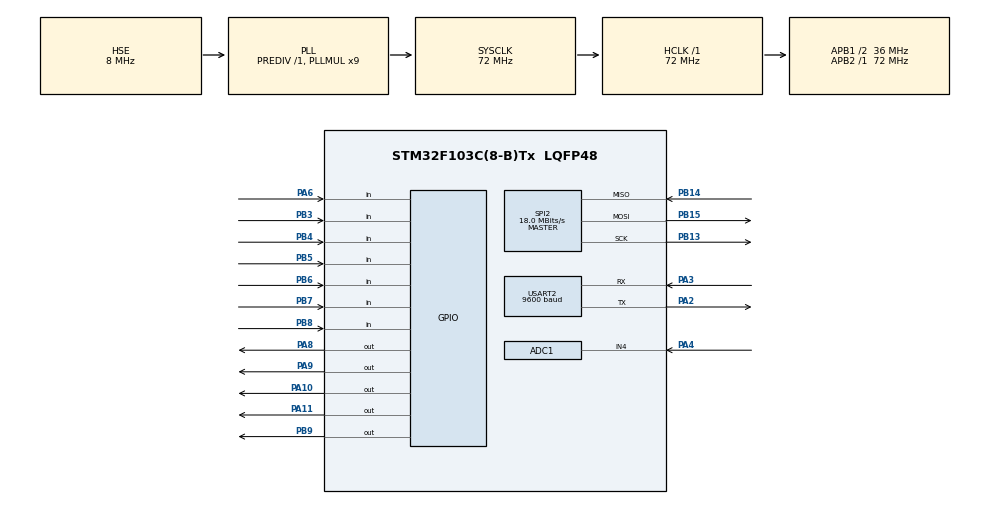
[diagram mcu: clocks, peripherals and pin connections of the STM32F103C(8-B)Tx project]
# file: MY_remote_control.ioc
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ADC1.Channel-0\#ChannelRegularConversion=ADC_CHANNEL_4
ADC1.NbrOfConversionFlag=1
ADC1.Rank-0\#ChannelRegularConversion=1
ADC1.SamplingTime-0\#ChannelRegularConversion=ADC_SAMPLETIME_1CYCLE_5
ADC1.master=1
Dma.Request0=SPI2_TX
Dma.SPI2_TX.0.Direction=DMA_MEMORY_TO_PERIPH
Dma.SPI2_TX.0.Instance=DMA1_Channel5
Dma.SPI2_TX.0.MemDataAlignment=DMA_MDATAALIGN_BYTE
Dma.SPI2_TX.0.MemInc=DMA_MINC_ENABLE
Dma.SPI2_TX.0.Mode=DMA_NORMAL
Dma.SPI2_TX.0.PeriphDataAlignment=DMA_PDATAALIGN_BYTE
Dma.SPI2_TX.0.PeriphInc=DMA_PINC_DISABLE
Dma.SPI2_TX.0.Priority=DMA_PRIORITY_LOW
FREERTOS.Tasks01=defaultTask,24,128,StartDefaultTask,Default,NULL,Dynamic,NULL,NULL
Mcu.Family=STM32F1
Mcu.Name=STM32F103C(8-B)Tx
Mcu.Package=LQFP48
NVIC.DMA1_Channel5_IRQn=true\:5\:0\:false\:false\:true\:true\:false\:true\:true
NVIC.PriorityGroup=NVIC_PRIORITYGROUP_4
NVIC.TIM2_IRQn=true\:5\:0\:false\:false\:true\:true\:true\:true\:true
NVIC.TIM4_IRQn=true\:15\:0\:false\:false\:true\:false\:false\:true\:true
NVIC.TimeBase=TIM4_IRQn
NVIC.TimeBaseIP=TIM4
NVIC.USART2_IRQn=true\:5\:0\:false\:false\:true\:true\:true\:true\:true
PA10.GPIO_ModeDefaultOutputPP=GPIO_MODE_OUTPUT_PP
PA10.GPIO_Speed=GPIO_SPEED_FREQ_HIGH
PA10.PinState=GPIO_PIN_RESET
PA10.Signal=GPIO_Output
PA11.GPIO_ModeDefaultOutputPP=GPIO_MODE_OUTPUT_PP
PA11.GPIO_Speed=GPIO_SPEED_FREQ_HIGH
PA11.PinState=GPIO_PIN_RESET
PA11.Signal=GPIO_Output
PA13.Mode=Serial_Wire
PA13.Signal=SYS_JTMS-SWDIO
PA14.Mode=Serial_Wire
PA14.Signal=SYS_JTCK-SWCLK
PA2.Mode=Asynchronous
PA2.Signal=USART2_TX
PA3.Mode=Asynchronous
PA3.Signal=USART2_RX
PA4.Signal=ADCx_IN4
PA6.GPIO_PuPd=GPIO_PULLUP
PA6.Signal=GPIO_Input
PA8.GPIO_ModeDefaultOutputPP=GPIO_MODE_OUTPUT_PP
PA8.GPIO_Speed=GPIO_SPEED_FREQ_HIGH
PA8.PinState=GPIO_PIN_RESET
PA8.Signal=GPIO_Output
PA9.GPIO_ModeDefaultOutputPP=GPIO_MODE_OUTPUT_PP
PA9.GPIO_Speed=GPIO_SPEED_FREQ_HIGH
PA9.PinState=GPIO_PIN_RESET
PA9.Signal=GPIO_Output
PB13.Mode=Full_Duplex_Master
PB13.Signal=SPI2_SCK
PB14.Mode=Full_Duplex_Master
PB14.Signal=SPI2_MISO
PB15.Mode=Full_Duplex_Master
PB15.Signal=SPI2_MOSI
PB3.GPIO_PuPd=GPIO_PULLUP
PB3.Signal=GPIO_Input
PB4.GPIO_PuPd=GPIO_PULLUP
PB4.Signal=GPIO_Input
PB5.GPIO_PuPd=GPIO_PULLUP
PB5.Signal=GPIO_Input
PB6.GPIO_PuPd=GPIO_PULLUP
PB6.Signal=GPIO_Input
PB7.GPIO_PuPd=GPIO_PULLUP
PB7.Signal=GPIO_Input
PB8.GPIO_PuPd=GPIO_PULLUP
PB8.Signal=GPIO_Input
PB9.Signal=GPIO_Output
PD0-OSC_IN.Mode=HSE-External-Oscillator
PD0-OSC_IN.Signal=RCC_OSC_IN
PD1-OSC_OUT.Mode=HSE-External-Oscillator
PD1-OSC_OUT.Signal=RCC_OSC_OUT
ProjectManager.HeapSize=0x200
ProjectManager.StackSize=0x400
ProjectManager.TargetToolchain=MDK-ARM V5.32
RCC.ADCPresc=RCC_ADCPCLK2_DIV6
RCC.AHBFreq_Value=72000000
RCC.APB1CLKDivider=RCC_HCLK_DIV2
RCC.APB1Freq_Value=36000000
RCC.APB1TimFreq_Value=72000000
RCC.APB2Freq_Value=72000000
RCC.APB2TimFreq_Value=72000000
RCC.HCLKFreq_Value=72000000
RCC.PLLMUL=RCC_PLL_MUL9
RCC.PLLSourceVirtual=RCC_PLLSOURCE_HSE
RCC.SYSCLKFreq_VALUE=72000000
RCC.SYSCLKSource=RCC_SYSCLKSOURCE_PLLCLK
RCC.USBFreq_Value=72000000
SH.ADCx_IN4.0=ADC1_IN4,IN4
SPI2.BaudRatePrescaler=SPI_BAUDRATEPRESCALER_2
SPI2.CalculateBaudRate=18.0 MBits/s
SPI2.Direction=SPI_DIRECTION_2LINES
SPI2.Mode=SPI_MODE_MASTER
SPI2.VirtualType=VM_MASTER
TIM2.Period=10000-1
TIM2.Prescaler=72-1
USART2.BaudRate=9600
USART2.VirtualMode=VM_ASYNC
VP_FREERTOS_VS_CMSIS_V2.Mode=CMSIS_V2
VP_SYS_VS_tim4.Mode=TIM4
VP_TIM2_VS_ClockSourceINT.Mode=Internal
board=custom

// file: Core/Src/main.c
/* USER CODE BEGIN Header */
/**
  ******************************************************************************
  * @file           : main.c
  * @brief          : Main program body
  ******************************************************************************
  * @attention
  *
  * Copyright (c) 2024 STMicroelectronics.
  * All rights reserved.
  *
  * This software is licensed under terms that can be found in the LICENSE file
  * in the root directory of this software component.
  * If no LICENSE file comes with this software, it is provided AS-IS.
  *
  ******************************************************************************
  */
/* USER CODE END Header */
#include "main.h"
#include "cmsis_os.h"
#include "adc.h"
#include "dma.h"
#include "spi.h"
#include "tim.h"
#include "usart.h"
#include "gpio.h"

void SystemClock_Config(void);
void MX_FREERTOS_Init(void);
/* USER CODE BEGIN PFP */
extern void GameSoundTimer_Func(void);
extern void Update_Key(void);
/* USER CODE END PFP */

int main(void)
{

  /* MCU Configuration--------------------------------------------------------*/

  /* Reset of all peripherals, Initializes the Flash interface and the Systick. */
  HAL_Init();

  /* Configure the system clock */
  SystemClock_Config();

  /* Initialize all configured peripherals */
  MX_GPIO_Init();
  MX_DMA_Init();
  MX_ADC1_Init();
  MX_USART2_UART_Init();
  MX_TIM2_Init();
  MX_SPI2_Init();

  /* Init scheduler */
  osKernelInitialize();

  /* Call init function for freertos objects (in cmsis_os2.c) */
  MX_FREERTOS_Init();

  /* Start scheduler */
  osKernelStart();

  /* We should never get here as control is now taken by the scheduler */

  /* Infinite loop */
  while (1)
  {

  }
}

void SystemClock_Config(void)
{
  RCC_OscInitTypeDef RCC_OscInitStruct = {0};
  RCC_ClkInitTypeDef RCC_ClkInitStruct = {0};
  RCC_PeriphCLKInitTypeDef PeriphClkInit = {0};

  /** Initializes the RCC Oscillators according to the specified parameters
  * in the RCC_OscInitTypeDef structure.
  */
  RCC_OscInitStruct.OscillatorType = RCC_OSCILLATORTYPE_HSE;
  RCC_OscInitStruct.HSEState = RCC_HSE_ON;
  RCC_OscInitStruct.HSEPredivValue = RCC_HSE_PREDIV_DIV1;
  RCC_OscInitStruct.HSIState = RCC_HSI_ON;
  RCC_OscInitStruct.PLL.PLLState = RCC_PLL_ON;
  RCC_OscInitStruct.PLL.PLLSource = RCC_PLLSOURCE_HSE;
  RCC_OscInitStruct.PLL.PLLMUL = RCC_PLL_MUL9;
  if (HAL_RCC_OscConfig(&RCC_OscInitStruct) != HAL_OK)
  {
    Error_Handler();
  }

  /** Initializes the CPU, AHB and APB buses clocks
  */
  RCC_ClkInitStruct.ClockType = RCC_CLOCKTYPE_HCLK|RCC_CLOCKTYPE_SYSCLK
                              |RCC_CLOCKTYPE_PCLK1|RCC_CLOCKTYPE_PCLK2;
  RCC_ClkInitStruct.SYSCLKSource = RCC_SYSCLKSOURCE_PLLCLK;
  RCC_ClkInitStruct.AHBCLKDivider = RCC_SYSCLK_DIV1;
  RCC_ClkInitStruct.APB1CLKDivider = RCC_HCLK_DIV2;
  RCC_ClkInitStruct.APB2CLKDivider = RCC_HCLK_DIV1;

  if (HAL_RCC_ClockConfig(&RCC_ClkInitStruct, FLASH_LATENCY_2) != HAL_OK)
  {
    Error_Handler();
  }
  PeriphClkInit.PeriphClockSelection = RCC_PERIPHCLK_ADC;
  PeriphClkInit.AdcClockSelection = RCC_ADCPCLK2_DIV6;
  if (HAL_RCCEx_PeriphCLKConfig(&PeriphClkInit) != HAL_OK)
  {
    Error_Handler();
  }
}

void HAL_TIM_PeriodElapsedCallback(TIM_HandleTypeDef *htim)
{
  if (htim->Instance == TIM4) {
    HAL_IncTick();
  }
  /* USER CODE BEGIN Callback 1 */
  if (htim->Instance == TIM2) {

    GameSoundTimer_Func();
    Update_Key();
  }
  /* USER CODE END Callback 1 */
}

void Error_Handler(void)
{
  __disable_irq();
  while (1)
  {
  }
}

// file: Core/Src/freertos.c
/* USER CODE BEGIN Header */
/**
  ******************************************************************************
  * File Name          : freertos.c
  * Description        : Code for freertos applications
  ******************************************************************************
  * @attention
  *
  * Copyright (c) 2024 STMicroelectronics.
  * All rights reserved.
  *
  * This software is licensed under terms that can be found in the LICENSE file
  * in the root directory of this software component.
  * If no LICENSE file comes with this software, it is provided AS-IS.
  *
  ******************************************************************************
  */
/* USER CODE END Header */

#include "FreeRTOS.h"
#include "task.h"
#include "main.h"
#include "cmsis_os.h"

/* USER CODE BEGIN Includes */
#include "MY_MainCode.h"
/* USER CODE END Includes */

/* Definitions for defaultTask */
osThreadId_t defaultTaskHandle;
const osThreadAttr_t defaultTask_attributes = {
  .name = "defaultTask",
  .stack_size = 128 * 4,
  .priority = (osPriority_t) osPriorityNormal,
};

void StartDefaultTask(void *argument);

void MX_FREERTOS_Init(void); /* (MISRA C 2004 rule 8.1) */

void MX_FREERTOS_Init(void) {

  /* Create the thread(s) */
  /* creation of defaultTask */
  defaultTaskHandle = osThreadNew(StartDefaultTask, NULL, &defaultTask_attributes);

  /* USER CODE BEGIN RTOS_THREADS */
  MY_MainCode_Init();
  /* add threads, ... */
  /* USER CODE END RTOS_THREADS */

}

void StartDefaultTask(void *argument)
{
  /* USER CODE BEGIN StartDefaultTask */
  /* Infinite loop */
  for(;;)
  {
    vTaskDelay(100);
  }
  /* USER CODE END StartDefaultTask */
}
